# GD32E511_512 register map
File version: 1.0
CPU: CM33 r0p4, little endian, MPU, FPU, 4 interrupt priority bits
Registers are 32-bit, read-write, reset 0x0 unless marked. A register's access mark holds for its fields unless they carry their own. Offsets are from the block's base; [hi:lo] are bit positions.

## PMU — Power management unit
Base 0x40007000
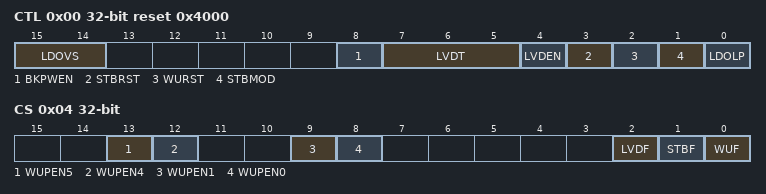
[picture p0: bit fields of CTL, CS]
0x00 CTL reset 0x4000 — Control register
  [15:14] LDOVS — LDO output voltage select
  [8] BKPWEN — Backup domain write enable
  [7:5] LVDT — Low voltage detector threshold
  [4] LVDEN — Low voltage detector enable
  [3] STBRST — Standby flag reset
  [2] WURST — Wakeup flag reset
  [1] STBMOD — Standby mode
  [0] LDOLP — LDO low power mode
0x04 CS access per field — Control and status register
  [13] WUPEN5 rw — WKUP Pin5 (PB5) enable
  [12] WUPEN4 rw — WKUP Pin4 (PC5) enable
  [9] WUPEN1 rw — WKUP Pin 1 (PC13) enable
  [8] WUPEN0 rw — WKUP Pin 0 (PA0) enable
  [2] LVDF ro — Low voltage detector status flag
  [1] STBF ro — Standby flag
  [0] WUF ro — Wakeup flag

## SPI0 — Serial peripheral interface
Base 0x40013000
Same registers: SPI2 0x40003C00
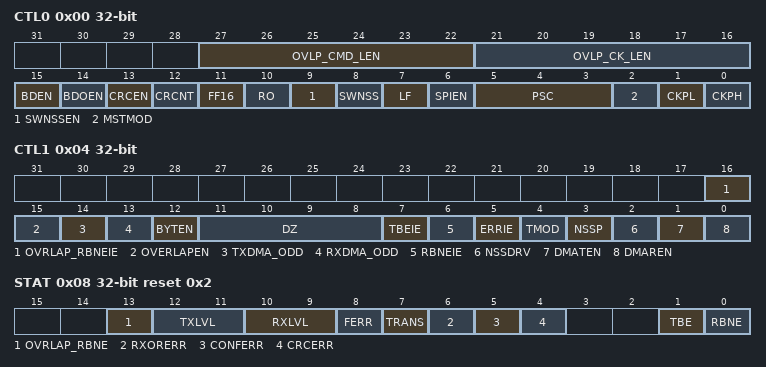
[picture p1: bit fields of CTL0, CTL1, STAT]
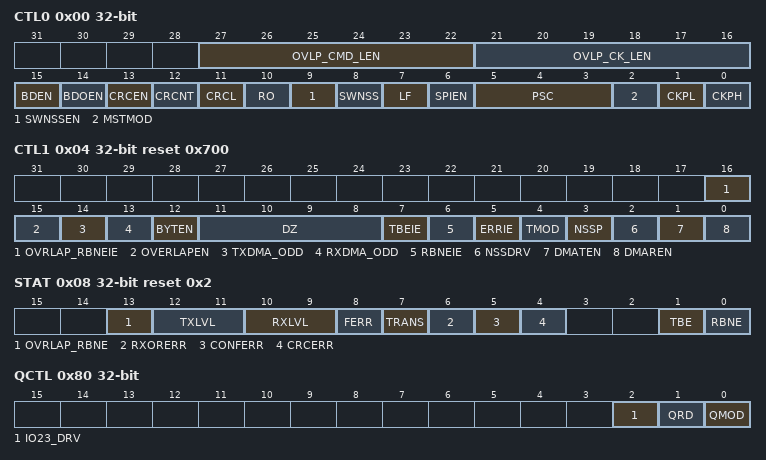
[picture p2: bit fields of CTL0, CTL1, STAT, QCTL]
0x00 CTL0 — Control register 0
  [27:22] OVLP_CMD_LEN — The length of command when overlap is enabled.
  [21:16] OVLP_CK_LEN — The length of SCK when overlap is enabled.
  [15] BDEN — Bidirectional enable
  [14] BDOEN — Bidirectional transmit output enable
  [13] CRCEN — CRC calculation enable
  [12] CRCNT — CRC next transfer
  [11] FF16 — Data frame format (for SPI0 and SPI2)
  [10] RO — Receive only
  [9] SWNSSEN — NSS software mode selection
  [8] SWNSS — NSS pin selection in NSS software mode
  [7] LF — LSB first mode
  [6] SPIEN — SPI enable
  [5:3] PSC — Master clock prescaler selection
  [2] MSTMOD — Master mode enable
  [1] CKPL — Clock polarity selection
  [0] CKPH — Clock phase selection
0x04 CTL1 — Control register 1
  [16] OVRLAP_RBNEIE — OVLPDATA not empty interrupt enable
  [15] OVERLAPEN — Overlap mode enable. When enabled, users can get the data on SPI bus from SPI_OVLPDATA0 and SPI_OVLPDATA1.
  [14] TXDMA_ODD — Odd bytes in TX DMA channel (for SPI1 and SPI3)
  [13] RXDMA_ODD — Odd bytes in RX DMA channel (for SPI1 and SPI3)
  [12] BYTEN — Byte access enable (for SPI1 and SPI3)
  [11:8] DZ — Date size (for SPI1 and SPI3)
  [7] TBEIE — Transmit buffer / TXFIFO empty interrupt enable
  [6] RBNEIE — Receive buffer / RXFIFO not empty interrupt enable
  [5] ERRIE — Errors interrupt enable.
  [4] TMOD — SPI TI mode enable.
  [3] NSSP — SPI NSS pulse mode enable.
  [2] NSSDRV — Drive NSS output
  [1] DMATEN — Transmit buffer / TXFIFO DMA enable
  [0] DMAREN — Receive buffer / RXFIFO DMA enable
0x08 STAT access per field reset 0x2 — Status register
  [13] OVRLAP_RBNE ro — OVLPDATA not empty
  [12:11] TXLVL ro — TXFIFO level (for SPI1 and SPI3)
  [10:9] RXLVL ro — RXFIFO level (for SPI1 and SPI3)
  [8] FERR rw — Format error
  [7] TRANS ro — Transmitting ongoing bit
  [6] RXORERR ro — Reception overrun error bit
  [5] CONFERR ro — SPI configuration error
  [4] CRCERR rw — SPI CRC error bit
  [1] TBE ro — Transmit buffer / TXFIFO empty
  [0] RBNE ro — Receive buffer / RXFIFO not empty
0x0C DATA
  [15:0] SPI_DATA — Data transfer register.
0x10 CRCPOLY reset 0x7 — CRC polynomial register
  [15:0] CRCPOLY
0x14 RCRC ro — RX CRC register
  [15:0] RCRC — RX CRC value
0x18 TCRC ro — TX CRC register
  [15:0] TCRC — TX CRC value

## SPI1 — Serial Peripheral Interface 1
Base 0x40003800
Same registers: SPI3 0x40004000
0x00 CTL0 — Control register 0
  [27:22] OVLP_CMD_LEN — The length of command when overlap is enabled.
  [21:16] OVLP_CK_LEN — The length of SCK when overlap is enabled.
  [15] BDEN — Bidirectional enable
  [14] BDOEN — Bidirectional transmit output enable
  [13] CRCEN — CRC calculation enable
  [12] CRCNT — CRC next transfer
  [11] CRCL — CRC length (for SPI1 and SPI3)
  [10] RO — Receive only
  [9] SWNSSEN — NSS software mode selection
  [8] SWNSS — NSS pin selection in NSS software mode
  [7] LF — LSB first mode
  [6] SPIEN — SPI enable
  [5:3] PSC — Master clock prescaler selection
  [2] MSTMOD — Master mode enable
  [1] CKPL — Clock polarity selection
  [0] CKPH — Clock phase selection
0x04 CTL1 reset 0x700 — Control register 1
  [16] OVRLAP_RBNEIE — OVLPDATA not empty interrupt enable
  [15] OVERLAPEN — Overlap mode enable. When enabled, users can get the data on SPI bus from SPI_OVLPDATA0 and SPI_OVLPDATA1.
  [14] TXDMA_ODD — Odd bytes in TX DMA channel (for SPI1 and SPI3)
  [13] RXDMA_ODD — Odd bytes in RX DMA channel (for SPI1 and SPI3)
  [12] BYTEN — Byte access enable (for SPI1 and SPI3)
  [11:8] DZ — Date size (for SPI1 and SPI3)
  [7] TBEIE — Transmit buffer / TXFIFO empty interrupt enable
  [6] RBNEIE — Receive buffer / RXFIFO not empty interrupt enable
  [5] ERRIE — Errors interrupt enable.
  [4] TMOD — SPI TI mode enable.
  [3] NSSP — SPI NSS pulse mode enable.
  [2] NSSDRV — Drive NSS output
  [1] DMATEN — Transmit buffer / TXFIFO DMA enable
  [0] DMAREN — Receive buffer / RXFIFO DMA enable
0x08 STAT access per field reset 0x2 — Status register
  [13] OVRLAP_RBNE ro — OVLPDATA not empty
  [12:11] TXLVL ro — TXFIFO level (for SPI1 and SPI3)
  [10:9] RXLVL ro — RXFIFO level (for SPI1 and SPI3)
  [8] FERR rw — Format error
  [7] TRANS ro — Transmitting ongoing bit
  [6] RXORERR ro — Reception overrun error bit
  [5] CONFERR ro — SPI configuration error
  [4] CRCERR rw — SPI CRC error bit
  [1] TBE ro — Transmit buffer / TXFIFO empty
  [0] RBNE ro — Receive buffer / RXFIFO not empty
0x0C DATA
  [15:0] SPI_DATA — Data transfer register.
0x10 CRCPOLY reset 0x7 — CRC polynomial register
  [15:0] CRCPOLY
0x14 RCRC ro — RX CRC register
  [15:0] RCRC — RX CRC value
0x18 TCRC ro — TX CRC register
  [15:0] TCRC — TX CRC value
0x1C OVLPDATA0 ro — Data overlap register 0
  [31:0] OVLPDATA0 — It receives the data transmited on the SPI bus when the BDEN in SPI_CTL0 is 1, and this is used when overlap mode is enabled in SPI_CTL1.
0x20 OVLPDATA1 ro — Data overlap register 1
  [31:0] OVLPDATA1 — It receives the data transmited on the SPI bus when the BDEN in SPI_CTL0 is 1, and this is used when overlap mode is enabled in SPI_CTL1.
0x80 QCTL — Quad-SPI mode control register
  [2] IO23_DRV — Drive IO2 and IO3 enable
  [1] QRD — Quad-SPI mode read select.
  [0] QMOD — Quad-SPI mode enable.
